VERSION ""

NS_ :

BS_:

BU_: ECU TCU BCM

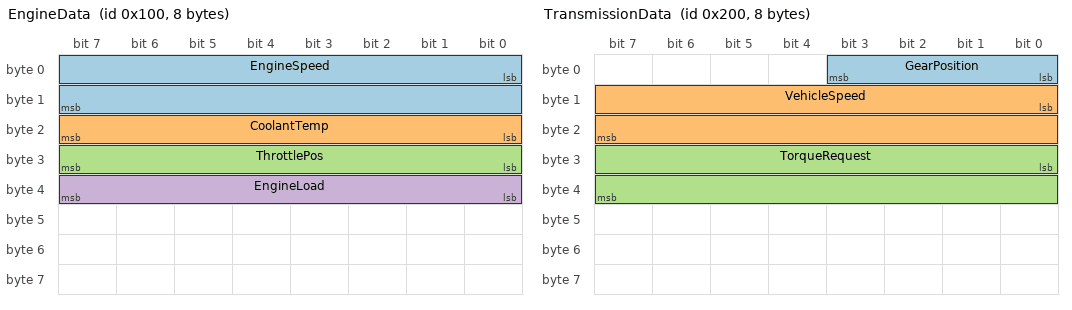
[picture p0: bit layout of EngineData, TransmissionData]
BO_ 256 EngineData: 8 ECU
 SG_ EngineSpeed : 0|16@1+ (0.25,0) [0|16383.75] "RPM" Vector__XXX
 SG_ CoolantTemp : 16|8@1+ (1,-40) [-40|215] "degC" Vector__XXX
 SG_ ThrottlePos : 24|8@1+ (0.392157,0) [0|100] "%" Vector__XXX
 SG_ EngineLoad : 32|8@1+ (0.392157,0) [0|100] "%" Vector__XXX

BO_ 512 TransmissionData: 8 TCU
 SG_ GearPosition : 0|4@1+ (1,0) [0|8] "" Vector__XXX
 SG_ VehicleSpeed : 8|16@1+ (0.01,0) [0|655.35] "km/h" Vector__XXX
 SG_ TorqueRequest : 24|16@1+ (0.1,-100) [-100|6553.5] "Nm" Vector__XXX

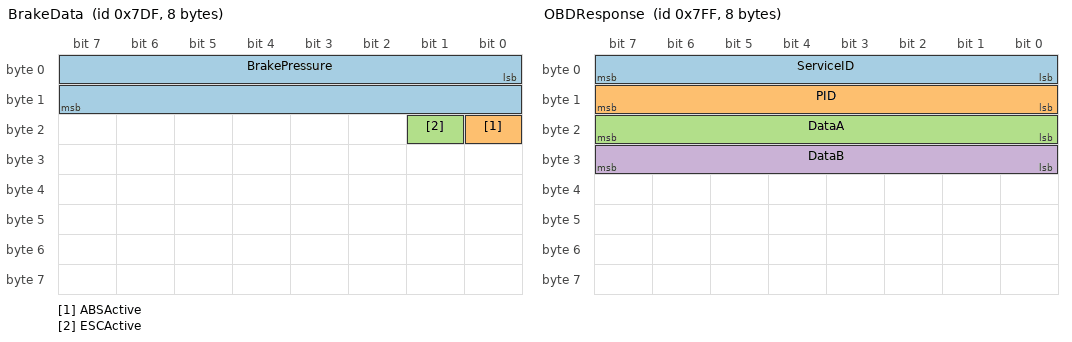
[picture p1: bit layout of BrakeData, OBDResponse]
BO_ 2015 BrakeData: 8 BCM
 SG_ BrakePressure : 0|16@1+ (0.01,0) [0|655.35] "bar" Vector__XXX
 SG_ ABSActive : 16|1@1+ (1,0) [0|1] "" Vector__XXX
 SG_ ESCActive : 17|1@1+ (1,0) [0|1] "" Vector__XXX

BO_ 2047 OBDResponse: 8 ECU
 SG_ ServiceID : 0|8@1+ (1,0) [0|255] "" Vector__XXX
 SG_ PID : 8|8@1+ (1,0) [0|255] "" Vector__XXX
 SG_ DataA : 16|8@1+ (1,0) [0|255] "" Vector__XXX
 SG_ DataB : 24|8@1+ (1,0) [0|255] "" Vector__XXX
